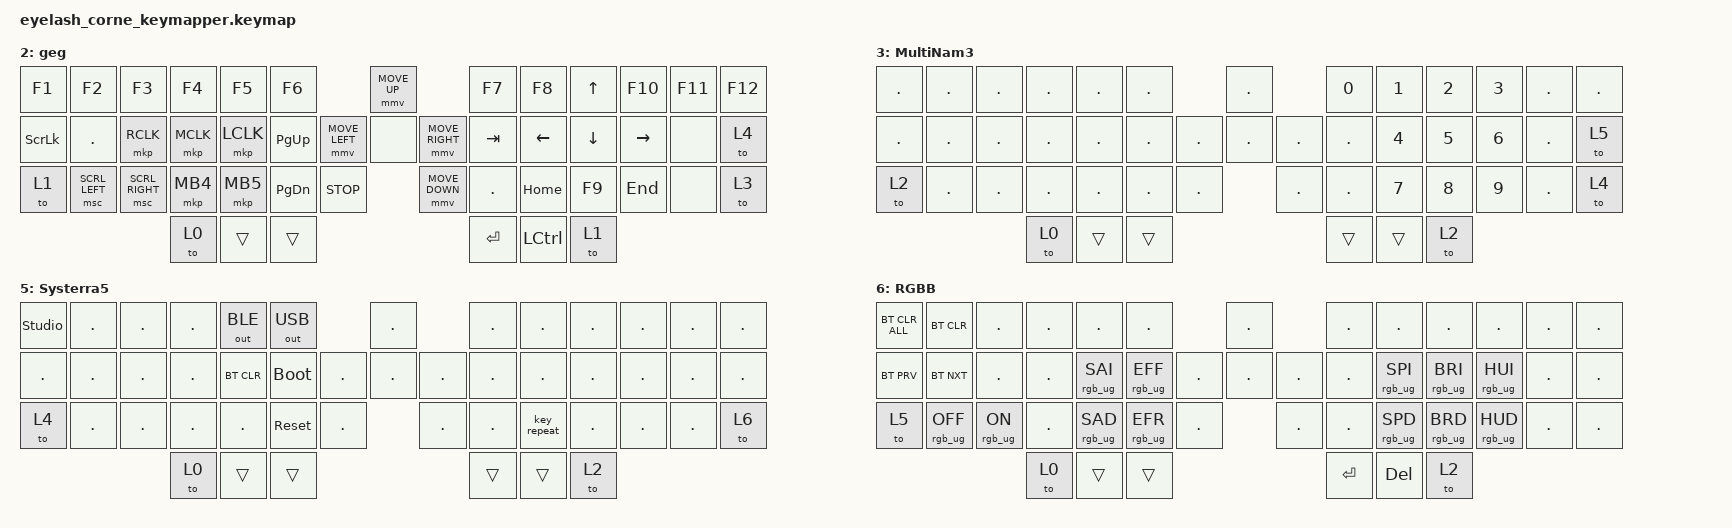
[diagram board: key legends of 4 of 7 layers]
#include <dt-bindings/zmk/mouse.h>
#include <input/processors.dtsi>
#include <behaviors.dtsi>
#include <dt-bindings/zmk/bt.h>
#include <dt-bindings/zmk/keys.h>
#include <dt-bindings/zmk/outputs.h>
#include <dt-bindings/zmk/pointing.h>
#include <dt-bindings/zmk/pointing.h>
#include <dt-bindings/zmk/pointing.h>
#include <dt-bindings/zmk/rgb.h>

/*

   &mmv_input_listener {
       input-processors = <&zip_xy_scaler 2 1>;
   };

   &msc_input_listener {
       input-processors = <&zip_xy_scaler 2 1>;
   };

 */

#define ZMK_MOUSE_DEFAULT_MOVE_VAL 1200  // 600
#define ZMK_MOUSE_DEFAULT_SCRL_VAL 20    // 10

/ {
    behaviors {
        tdshiftcaps: tdshiftcaps {
            compatible = "zmk,behavior-tap-dance";
            display-name = "Shift/Caps Lock Tap Dance";
            #binding-cells = <0>;
            bindings = <&kp LEFT_SHIFT>, <&kp CAPS>;
        };

        holdtap: holdtap {
            compatible = "zmk,behavior-hold-tap";
            label = "HOLDTAP";
            bindings = <&kp>, <&kp>;

            #binding-cells = <2>;
            tapping-term-ms = <200>;
        };
    };

    rgb_encoder: rgb_encoder {
        compatible = "zmk,behavior-sensor-rotate";
        #sensor-binding-cells = <0>;
        bindings = <&rgb_ug RGB_BRI>, <&rgb_ug RGB_BRD>;
    };

    scroll_encoder: scroll_encoder {
        compatible = "zmk,behavior-sensor-rotate";
        #sensor-binding-cells = <0>;
        bindings = <&msc SCRL_DOWN>, <&msc SCRL_UP>;

        tap-ms = <30>;
    };

    macros {
        zmisc_HighContrast: zmisc_HighContrast {
            compatible = "zmk,behavior-macro";
            #binding-cells = <0>;
            bindings = <&kp LA(LS(PRINTSCREEN))>;
            label = "ZMISC_HIGHCONTRAST";
        };
    };

    keymap {
        compatible = "zmk,keymap";

        Zer0 {
            display-name = "SveaHej";
            bindings = <
&kp TAB        &kp RA(W)                 &kp P  &kp O                                        &kp U           &kp Y                                                          &kp UP               &kp Q      &kp G      &kp D  &kp L  &kp W         &holdtap AT_SIGN EXCL
&kp BACKSPACE  &kp A                     &kp H  &kp E                                        &kp I           &holdtap SEMI COMMA                                  &kp LEFT  &none     &kp RIGHT  &kp F      &kp S      &kp T  &kp N  &kp R         &holdtap SLASH MINUS
&tdshiftcaps   &holdtap BACKSPACE RA(P)  &kp J  &kp RA(Q)                                    &kp K           &holdtap COLON DOT               &kp C_PLAY_PAUSE              &kp DOWN             &kp B      &kp C      &kp M  &kp V  &holdtap Z X  &holdtap ASTRK APOS
                                                &holdtap LC(LS(LA(LEFT_COMMAND))) BACKSPACE  &sk LEFT_SHIFT  &holdtap LC(LS(LEFT_ALT)) SPACE                                                     &kp ENTER  &sk LCTRL  &to 1
            >;

            sensor-bindings = <&inc_dec_kp C_VOLUME_UP C_VOLUME_DOWN>;
        };

        S1M {
            display-name = "SYM";
            bindings = <
&kp DOT     &kp EXCL       &kp AT   &kp HASH  &kp DLLR                      &kp PRCNT                                &mmv MOVE_UP                     &kp CARET  &kp AMPS      &kp ASTRK  &kp LPAR  &kp RPAR  &holdtap BSPC GRAVE
&kp DELETE  &kp DOT        &kp DOT  &kp DOT   &kp DOT                       &kp DOT                  &mmv MOVE_LEFT  &mkp LCLK       &mmv MOVE_RIGHT  &kp MINUS  &kp EQUAL     &kp LBKT   &kp RBKT  &kp BSLH  &to 4
&kp DOT     &kp BACKSPACE  &kp DOT  &kp DOT   &kp DOT                       &kp DOT    &kp K_MUTE                    &mmv MOVE_DOWN                   &kp UNDER  &kp PLUS      &kp LBRC   &kp RBRC  &kp PIPE  &to 3
                                    &to 0     &kp LS(LA(LC(LEFT_COMMAND)))  &trans                                                                    &kp ENTER  &kp LEFT_ALT  &to 2
            >;

            sensor-bindings = <&rgb_encoder>;
            label = "Symba11";
        };

        Nav2 {
            label = "2HeyListen";
            display-name = "geg";
            bindings = <
&kp F1          &kp F2          &kp F3           &kp F4     &kp F5     &kp F6                                       &mmv MOVE_UP                     &kp F7     &kp F8     &kp UP_ARROW    &kp F10          &kp F11  &kp F12
&kp SCROLLLOCK  &kp DOT         &mkp RCLK        &mkp MCLK  &mkp LCLK  &kp PAGE_UP                  &mmv MOVE_LEFT  &none           &mmv MOVE_RIGHT  &kp TAB    &kp LEFT   &kp DOWN_ARROW  &kp RIGHT_ARROW  &none    &to 4
&to 1           &msc SCRL_LEFT  &msc SCRL_RIGHT  &mkp MB4   &mkp MB5   &kp PAGE_DOWN  &kp C_STOP                    &mmv MOVE_DOWN                   &kp DOT    &kp HOME   &kp F9          &kp END          &none    &to 3
                                                 &to 0      &trans     &trans                                                                        &kp ENTER  &kp LCTRL  &to 1
            >;

            sensor-bindings = <&inc_dec_kp K_SCROLL_UP K_SCROLL_DOWN>;
        };

        MultiNam3 {
            bindings = <
&kp DOT  &kp DOT  &kp DOT  &kp DOT  &kp DOT  &kp DOT                      &kp DOT           &kp N0      &kp N1  &kp N2  &kp N3  &kp DOT  &kp DOT
&kp DOT  &kp DOT  &kp DOT  &kp DOT  &kp DOT  &kp DOT             &kp DOT  &kp DOT  &kp DOT  &kp PERIOD  &kp N4  &kp N5  &kp N6  &kp DOT  &to 5
&to 2    &kp DOT  &kp DOT  &kp DOT  &kp DOT  &kp DOT  &kp DOT             &kp DOT           &kp DOT     &kp N7  &kp N8  &kp N9  &kp DOT  &to 4
                           &to 0    &trans   &trans                                         &trans      &trans  &to 2
            >;

            label = "MultiNam3";
        };

        EatMy4ts {
            bindings = <
&rgb_ug RGB_colour_HSB(183,49,56)&rgb_ug RGB_colour_HSB(303,58,40)&rgb_ug RGB_colour_HSB(309,78,47)&rgb_ug RGB_colour_HSB(192,66,45)&kp DOT&kp DOT&kp DOT&kp DOT&kp DOT&kp DOT&kp DOT&kp DOT&kp DOT
&kp DOT                           &kp DOT                           &kp DOT                           &kp DOT                           &kp DOT  &kp DOT             &kp DOT  &kp DOT  &kp DOT  &kp DOT  &kp DOT  &kp DOT  &kp DOT  &kp DOT  &to 6
&to 3                             &kp PAUSE_BREAK                   &kp PRINTSCREEN                   &kp DOT                           &kp DOT  &kp DOT  &kp DOT             &kp DOT           &kp DOT  &kp DOT  &kp DOT  &kp DOT  &kp DOT  &to 5
                                                                                                      &to 0                             &trans   &trans                                         &trans   &trans   &to 2
            >;

            label = "EatMy4ts";
        };

        SY5 {
            bindings = <
&studio_unlock  &kp DOT  &kp DOT  &kp DOT  &out OUT_BLE  &out OUT_USB                      &kp DOT           &kp DOT  &kp DOT      &kp DOT  &kp DOT  &kp DOT  &kp DOT
&kp DOT         &kp DOT  &kp DOT  &kp DOT  &bt BT_CLR    &bootloader              &kp DOT  &kp DOT  &kp DOT  &kp DOT  &kp DOT      &kp DOT  &kp DOT  &kp DOT  &kp DOT
&to 4           &kp DOT  &kp DOT  &kp DOT  &kp DOT       &sys_reset    &kp DOT             &kp DOT           &kp DOT  &key_repeat  &kp DOT  &kp DOT  &kp DOT  &to 6
                                  &to 0    &trans        &trans                                              &trans   &trans       &to 2
            >;

            label = "Systerra5";
        };

        R6BB {
            display-name = "RGBB";
            bindings = <
&bt BT_CLR_ALL  &bt BT_CLR       &kp DOT         &kp DOT  &kp DOT          &kp DOT                              &kp DOT           &kp DOT    &kp DOT          &kp DOT          &kp DOT          &kp DOT  &kp DOT
&bt BT_PRV      &bt BT_NXT       &kp DOT         &kp DOT  &rgb_ug RGB_SAI  &rgb_ug RGB_EFF             &kp DOT  &kp DOT  &kp DOT  &kp DOT    &rgb_ug RGB_SPI  &rgb_ug RGB_BRI  &rgb_ug RGB_HUI  &kp DOT  &kp DOT
&to 5           &rgb_ug RGB_OFF  &rgb_ug RGB_ON  &kp DOT  &rgb_ug RGB_SAD  &rgb_ug RGB_EFR  &kp DOT             &kp DOT           &kp DOT    &rgb_ug RGB_SPD  &rgb_ug RGB_BRD  &rgb_ug RGB_HUD  &kp DOT  &kp DOT
                                                 &to 0    &trans           &trans                                                 &kp ENTER  &kp DEL          &to 2
            >;

            sensor-bindings = <&scroll_encoder>;
            label = "R6BB";
        };
    };
};
